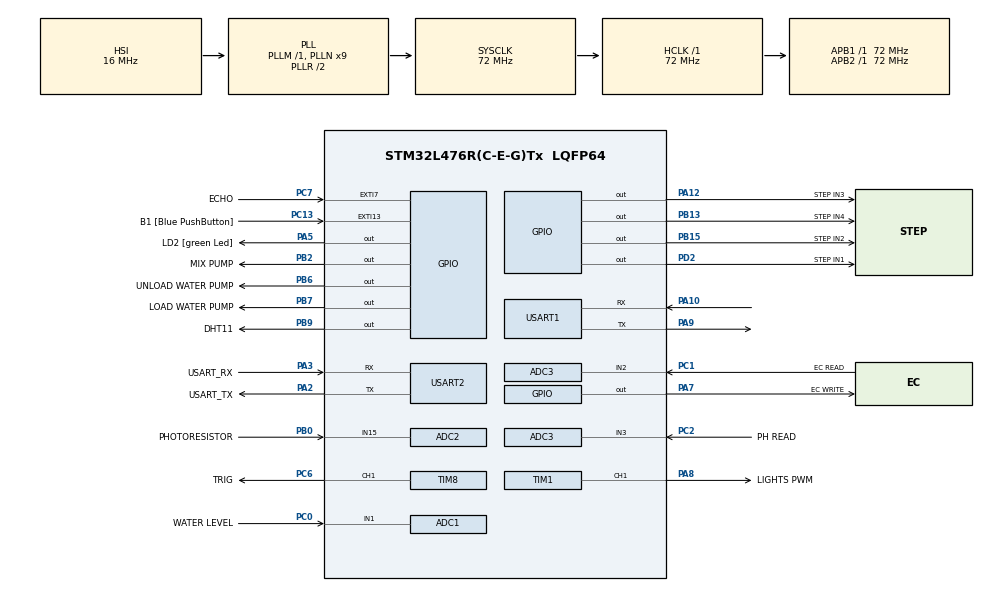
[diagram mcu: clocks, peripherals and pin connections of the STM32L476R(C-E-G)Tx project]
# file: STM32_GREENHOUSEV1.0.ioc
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ADC1.Channel-0\#ChannelRegularConversion=ADC_CHANNEL_1
ADC1.NbrOfConversionFlag=1
ADC1.OffsetNumber-0\#ChannelRegularConversion=ADC_OFFSET_NONE
ADC1.Rank-0\#ChannelRegularConversion=1
ADC1.Resolution=ADC_RESOLUTION_10B
ADC1.SamplingTime-0\#ChannelRegularConversion=ADC_SAMPLETIME_2CYCLES_5
ADC1.master=1
ADC2.Channel-0\#ChannelRegularConversion=ADC_CHANNEL_15
ADC2.ClockPrescaler=ADC_CLOCK_ASYNC_DIV1
ADC2.NbrOfConversionFlag=1
ADC2.OffsetNumber-0\#ChannelRegularConversion=ADC_OFFSET_NONE
ADC2.Rank-0\#ChannelRegularConversion=1
ADC2.Resolution=ADC_RESOLUTION_10B
ADC2.SamplingTime-0\#ChannelRegularConversion=ADC_SAMPLETIME_2CYCLES_5
ADC3.Channel-1\#ChannelRegularConversion=ADC_CHANNEL_2
ADC3.ContinuousConvMode=DISABLE
ADC3.EOCSelection=ADC_EOC_SEQ_CONV
ADC3.NbrOfConversion=1
ADC3.NbrOfConversionFlag=1
ADC3.OffsetNumber-1\#ChannelRegularConversion=ADC_OFFSET_NONE
ADC3.Rank-1\#ChannelRegularConversion=1
ADC3.Resolution=ADC_RESOLUTION_10B
ADC3.SamplingTime-1\#ChannelRegularConversion=ADC_SAMPLETIME_2CYCLES_5
Dma.Request0=TIM1_CH1
Dma.TIM1_CH1.0.Direction=DMA_MEMORY_TO_PERIPH
Dma.TIM1_CH1.0.Instance=DMA1_Channel2
Dma.TIM1_CH1.0.MemDataAlignment=DMA_MDATAALIGN_WORD
Dma.TIM1_CH1.0.MemInc=DMA_MINC_ENABLE
Dma.TIM1_CH1.0.Mode=DMA_NORMAL
Dma.TIM1_CH1.0.PeriphDataAlignment=DMA_PDATAALIGN_WORD
Dma.TIM1_CH1.0.PeriphInc=DMA_PINC_DISABLE
Dma.TIM1_CH1.0.Priority=DMA_PRIORITY_LOW
Mcu.Family=STM32L4
Mcu.Name=STM32L476R(C-E-G)Tx
Mcu.Package=LQFP64
NVIC.ADC1_2_IRQn=true\:0\:0\:false\:false\:true\:true\:true\:true
NVIC.ADC3_IRQn=true\:0\:0\:false\:false\:true\:true\:true\:true
NVIC.DMA1_Channel2_IRQn=true\:0\:0\:false\:false\:true\:false\:true\:true
NVIC.EXTI15_10_IRQn=true\:0\:0\:false\:false\:true\:true\:true\:true
NVIC.EXTI9_5_IRQn=true\:0\:0\:false\:false\:true\:true\:true\:true
NVIC.PriorityGroup=NVIC_PRIORITYGROUP_4
PA10.Mode=Asynchronous
PA10.Signal=USART1_RX
PA12.GPIO_Label=STEP IN3
PA12.Signal=GPIO_Output
PA13\ (JTMS-SWDIO).GPIO_Label=TMS
PA13\ (JTMS-SWDIO).Mode=Serial_Wire
PA13\ (JTMS-SWDIO).Signal=SYS_JTMS-SWDIO
PA14\ (JTCK-SWCLK).GPIO_Label=TCK
PA14\ (JTCK-SWCLK).Mode=Serial_Wire
PA14\ (JTCK-SWCLK).Signal=SYS_JTCK-SWCLK
PA2.GPIO_Label=USART_TX
PA2.GPIO_Mode=GPIO_MODE_AF_PP
PA2.GPIO_PuPd=GPIO_NOPULL
PA2.GPIO_Speed=GPIO_SPEED_FREQ_VERY_HIGH
PA2.Mode=Asynchronous
PA2.Signal=USART2_TX
PA3.GPIO_Label=USART_RX
PA3.GPIO_Mode=GPIO_MODE_AF_PP
PA3.GPIO_PuPd=GPIO_NOPULL
PA3.GPIO_Speed=GPIO_SPEED_FREQ_VERY_HIGH
PA3.Mode=Asynchronous
PA3.Signal=USART2_RX
PA5.GPIO_Label=LD2 [green Led]
PA5.GPIO_ModeDefaultOutputPP=GPIO_MODE_OUTPUT_PP
PA5.GPIO_PuPd=GPIO_NOPULL
PA5.GPIO_Speed=GPIO_SPEED_FREQ_LOW
PA5.Signal=GPIO_Output
PA7.GPIO_Label=EC WRITE
PA7.Signal=GPIO_Output
PA8.GPIO_Label=LIGHTS PWM
PA8.Signal=S_TIM1_CH1
PA9.Mode=Asynchronous
PA9.Signal=USART1_TX
PB0.GPIO_Label=PHOTORESISTOR
PB0.Signal=ADCx_IN15
PB13.GPIO_Label=STEP IN4
PB13.Signal=GPIO_Output
PB15.GPIO_Label=STEP IN2
PB15.Signal=GPIO_Output
PB2.GPIO_Label=MIX PUMP
PB2.Signal=GPIO_Output
PB3\ (JTDO-TRACESWO).GPIO_Label=SWO
PB3\ (JTDO-TRACESWO).Signal=SYS_JTDO-SWO
PB6.GPIO_Label=UNLOAD WATER PUMP
PB6.Signal=GPIO_Output
PB7.GPIO_Label=LOAD WATER PUMP
PB7.Signal=GPIO_Output
PB9.GPIO_Label=DHT11
PB9.Signal=GPIO_Output
PC0.GPIO_Label=WATER LEVEL
PC0.Signal=ADCx_IN1
PC1.GPIO_Label=EC READ
PC1.Signal=ADCx_IN2
PC13.GPIO_Label=B1 [Blue PushButton]
PC13.GPIO_ModeDefaultEXTI=GPIO_MODE_IT_FALLING
PC13.GPIO_PuPd=GPIO_NOPULL
PC13.Signal=GPXTI13
PC14-OSC32_IN\ (PC14).Mode=LSE-External-Oscillator
PC14-OSC32_IN\ (PC14).Signal=RCC_OSC32_IN
PC15-OSC32_OUT\ (PC15).Mode=LSE-External-Oscillator
PC15-OSC32_OUT\ (PC15).Signal=RCC_OSC32_OUT
PC2.GPIO_Label=PH READ
PC2.Signal=ADCx_IN3
PC6.GPIO_Label=TRIG
PC6.Signal=S_TIM8_CH1
PC7.GPIO_Label=ECHO
PC7.GPIO_ModeDefaultEXTI=GPIO_MODE_IT_RISING_FALLING
PC7.Signal=GPXTI7
PD2.GPIO_Label=STEP IN1
PD2.Signal=GPIO_Output
PH0-OSC_IN\ (PH0).Signal=RCC_OSC_IN
PH1-OSC_OUT\ (PH1).Signal=RCC_OSC_OUT
ProjectManager.HeapSize=0x200
ProjectManager.StackSize=0x400
ProjectManager.TargetToolchain=STM32CubeIDE
RCC.ADCFreq_Value=64000000
RCC.AHBFreq_Value=72000000
RCC.APB1Freq_Value=72000000
RCC.APB1TimFreq_Value=72000000
RCC.APB2Freq_Value=72000000
RCC.APB2TimFreq_Value=72000000
RCC.CortexFreq_Value=72000000
RCC.HCLKFreq_Value=72000000
RCC.HSE_VALUE=8000000
RCC.HSI_VALUE=16000000
RCC.MSI_VALUE=4000000
RCC.PLLN=9
RCC.PLLSourceVirtual=RCC_PLLSOURCE_HSI
RCC.PREFETCH_ENABLE=1
RCC.SYSCLKFreq_VALUE=72000000
RCC.SYSCLKSource=RCC_SYSCLKSOURCE_PLLCLK
RCC.USBFreq_Value=64000000
RCC.VCOOutputFreq_Value=144000000
SH.ADCx_IN1.0=ADC1_IN1,IN1-Single-Ended
SH.ADCx_IN15.0=ADC2_IN15,IN15-Single-Ended
SH.ADCx_IN2.0=ADC3_IN2,IN2-Single-Ended
SH.ADCx_IN3.0=ADC3_IN3,IN3-Single-Ended
SH.S_TIM1_CH1.0=TIM1_CH1,PWM Generation1 CH1
SH.S_TIM8_CH1.0=TIM8_CH1,PWM Generation1 CH1
TIM1.Channel-PWM\ Generation1\ CH1=TIM_CHANNEL_1
TIM1.Period=90-1
TIM1.Pulse-PWM\ Generation1\ CH1=54
TIM2.Prescaler=71
TIM8.Channel-PWM\ Generation1\ CH1=TIM_CHANNEL_1
TIM8.Period=0xffff - 1
TIM8.Prescaler=72-1
TIM8.Pulse-PWM\ Generation1\ CH1=1
USART1.VirtualMode-Asynchronous=VM_ASYNC
USART2.VirtualMode-Asynchronous=VM_ASYNC
VP_TIM1_VS_ClockSourceINT.Mode=Internal
VP_TIM2_VS_ClockSourceINT.Mode=Internal
board=NUCLEO-L476RG

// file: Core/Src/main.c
/* USER CODE BEGIN Header */
/**
  ******************************************************************************
  * @file           : main.c
  * @brief          : Main program body
  ******************************************************************************
  * @attention
  *
  * Copyright (c) 2023 STMicroelectronics.
  * All rights reserved.
  *
  * This software is licensed under terms that can be found in the LICENSE file
  * in the root directory of this software component.
  * If no LICENSE file comes with this software, it is provided AS-IS.
  *
  ******************************************************************************
  */
/* USER CODE END Header */
#include "main.h"
#include "adc.h"
#include "dma.h"
#include "tim.h"
#include "usart.h"
#include "gpio.h"

/* USER CODE BEGIN Includes */
#include "virtual_main.h"
#include "dht11.h"
#include "ultrasonic.h"
/* USER CODE END Includes */

void SystemClock_Config(void);
void PeriphCommonClock_Config(void);

int main(void)
{

  /* MCU Configuration--------------------------------------------------------*/

  /* Reset of all peripherals, Initializes the Flash interface and the Systick. */
  HAL_Init();

  /* Configure the system clock */
  SystemClock_Config();

/* Configure the peripherals common clocks */
  PeriphCommonClock_Config();

  /* Initialize all configured peripherals */
  MX_GPIO_Init();
  MX_DMA_Init();
  MX_USART2_UART_Init();
  MX_TIM1_Init();
  MX_ADC2_Init();
  MX_ADC3_Init();
  MX_TIM2_Init();
  MX_ADC1_Init();
  MX_TIM8_Init();
  MX_USART1_UART_Init();
  /* USER CODE BEGIN 2 */
  HAL_TIM_Base_Start(&htim2);
  HAL_TIM_PWM_Start_IT(&htim8, TIM_CHANNEL_1);
  setup_pwm();

  /* USER CODE END 2 */

  /* Infinite loop */
  /* USER CODE BEGIN WHILE */
  while (1)
  {
	  virtual_main();
    /* USER CODE END WHILE */

  }
}

void SystemClock_Config(void)
{
  RCC_OscInitTypeDef RCC_OscInitStruct = {0};
  RCC_ClkInitTypeDef RCC_ClkInitStruct = {0};

  /** Configure the main internal regulator output voltage
  */
  if (HAL_PWREx_ControlVoltageScaling(PWR_REGULATOR_VOLTAGE_SCALE1) != HAL_OK)
  {
    Error_Handler();
  }

  /** Initializes the RCC Oscillators according to the specified parameters
  * in the RCC_OscInitTypeDef structure.
  */
  RCC_OscInitStruct.OscillatorType = RCC_OSCILLATORTYPE_HSI;
  RCC_OscInitStruct.HSIState = RCC_HSI_ON;
  RCC_OscInitStruct.HSICalibrationValue = RCC_HSICALIBRATION_DEFAULT;
  RCC_OscInitStruct.PLL.PLLState = RCC_PLL_ON;
  RCC_OscInitStruct.PLL.PLLSource = RCC_PLLSOURCE_HSI;
  RCC_OscInitStruct.PLL.PLLM = 1;
  RCC_OscInitStruct.PLL.PLLN = 9;
  RCC_OscInitStruct.PLL.PLLP = RCC_PLLP_DIV7;
  RCC_OscInitStruct.PLL.PLLQ = RCC_PLLQ_DIV2;
  RCC_OscInitStruct.PLL.PLLR = RCC_PLLR_DIV2;
  if (HAL_RCC_OscConfig(&RCC_OscInitStruct) != HAL_OK)
  {
    Error_Handler();
  }

  /** Initializes the CPU, AHB and APB buses clocks
  */
  RCC_ClkInitStruct.ClockType = RCC_CLOCKTYPE_HCLK|RCC_CLOCKTYPE_SYSCLK
                              |RCC_CLOCKTYPE_PCLK1|RCC_CLOCKTYPE_PCLK2;
  RCC_ClkInitStruct.SYSCLKSource = RCC_SYSCLKSOURCE_PLLCLK;
  RCC_ClkInitStruct.AHBCLKDivider = RCC_SYSCLK_DIV1;
  RCC_ClkInitStruct.APB1CLKDivider = RCC_HCLK_DIV1;
  RCC_ClkInitStruct.APB2CLKDivider = RCC_HCLK_DIV1;

  if (HAL_RCC_ClockConfig(&RCC_ClkInitStruct, FLASH_LATENCY_4) != HAL_OK)
  {
    Error_Handler();
  }
}

void PeriphCommonClock_Config(void)
{
  RCC_PeriphCLKInitTypeDef PeriphClkInit = {0};

  /** Initializes the peripherals clock
  */
  PeriphClkInit.PeriphClockSelection = RCC_PERIPHCLK_ADC;
  PeriphClkInit.AdcClockSelection = RCC_ADCCLKSOURCE_PLLSAI1;
  PeriphClkInit.PLLSAI1.PLLSAI1Source = RCC_PLLSOURCE_HSI;
  PeriphClkInit.PLLSAI1.PLLSAI1M = 1;
  PeriphClkInit.PLLSAI1.PLLSAI1N = 8;
  PeriphClkInit.PLLSAI1.PLLSAI1P = RCC_PLLP_DIV7;
  PeriphClkInit.PLLSAI1.PLLSAI1Q = RCC_PLLQ_DIV2;
  PeriphClkInit.PLLSAI1.PLLSAI1R = RCC_PLLR_DIV2;
  PeriphClkInit.PLLSAI1.PLLSAI1ClockOut = RCC_PLLSAI1_ADC1CLK;
  if (HAL_RCCEx_PeriphCLKConfig(&PeriphClkInit) != HAL_OK)
  {
    Error_Handler();
  }
}

void Error_Handler(void)
{
  __disable_irq();
  while (1)
  {
  }
}
